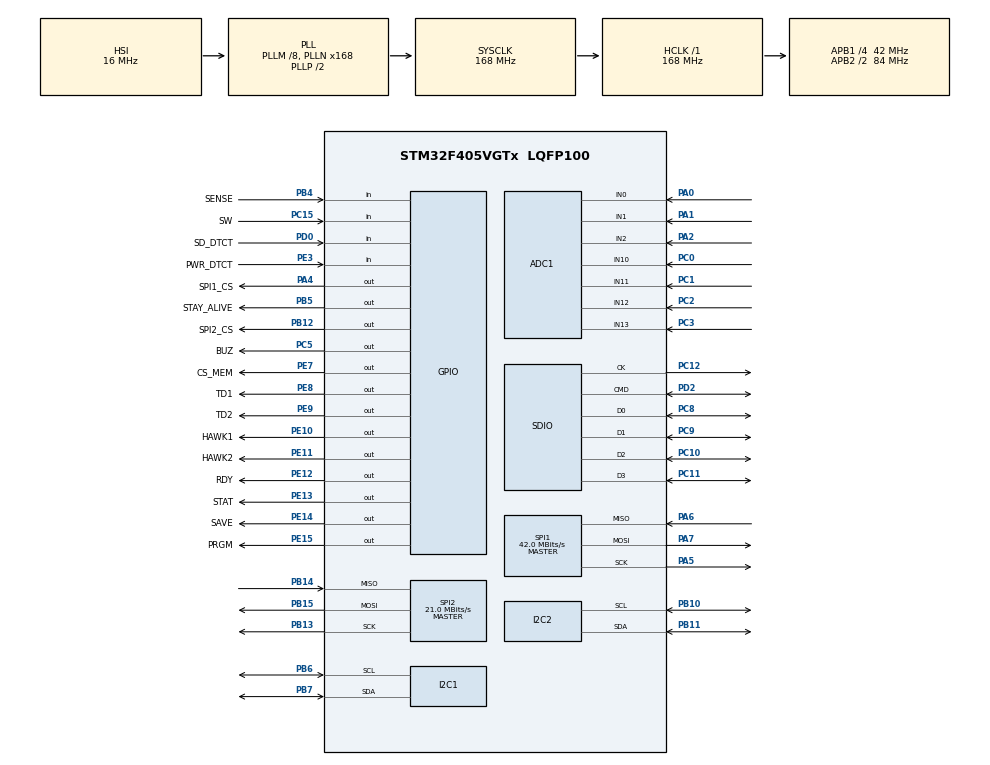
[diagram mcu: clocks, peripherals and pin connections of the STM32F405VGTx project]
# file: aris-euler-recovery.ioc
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ADC1.Channel-0\#ChannelRegularConversion=ADC_CHANNEL_0
ADC1.Channel-1\#ChannelRegularConversion=ADC_CHANNEL_1
ADC1.Channel-2\#ChannelRegularConversion=ADC_CHANNEL_2
ADC1.Channel-3\#ChannelRegularConversion=ADC_CHANNEL_10
ADC1.Channel-4\#ChannelRegularConversion=ADC_CHANNEL_11
ADC1.Channel-5\#ChannelRegularConversion=ADC_CHANNEL_12
ADC1.Channel-6\#ChannelRegularConversion=ADC_CHANNEL_13
ADC1.Channel-7\#ChannelRegularConversion=ADC_CHANNEL_TEMPSENSOR
ADC1.ContinuousConvMode=ENABLE
ADC1.DMAContinuousRequests=ENABLE
ADC1.NbrOfConversion=8
ADC1.NbrOfConversionFlag=1
ADC1.Rank-0\#ChannelRegularConversion=1
ADC1.Rank-1\#ChannelRegularConversion=2
ADC1.Rank-2\#ChannelRegularConversion=3
ADC1.Rank-3\#ChannelRegularConversion=4
ADC1.Rank-4\#ChannelRegularConversion=5
ADC1.Rank-5\#ChannelRegularConversion=6
ADC1.Rank-6\#ChannelRegularConversion=7
ADC1.Rank-7\#ChannelRegularConversion=8
ADC1.SamplingTime-0\#ChannelRegularConversion=ADC_SAMPLETIME_480CYCLES
ADC1.SamplingTime-1\#ChannelRegularConversion=ADC_SAMPLETIME_480CYCLES
ADC1.SamplingTime-2\#ChannelRegularConversion=ADC_SAMPLETIME_480CYCLES
ADC1.SamplingTime-3\#ChannelRegularConversion=ADC_SAMPLETIME_480CYCLES
ADC1.SamplingTime-4\#ChannelRegularConversion=ADC_SAMPLETIME_480CYCLES
ADC1.SamplingTime-5\#ChannelRegularConversion=ADC_SAMPLETIME_480CYCLES
ADC1.SamplingTime-6\#ChannelRegularConversion=ADC_SAMPLETIME_480CYCLES
ADC1.SamplingTime-7\#ChannelRegularConversion=ADC_SAMPLETIME_480CYCLES
ADC1.ScanConvMode=ENABLE
ADC1.master=1
Dma.ADC1.0.Direction=DMA_PERIPH_TO_MEMORY
Dma.ADC1.0.FIFOMode=DMA_FIFOMODE_DISABLE
Dma.ADC1.0.Instance=DMA2_Stream0
Dma.ADC1.0.MemDataAlignment=DMA_MDATAALIGN_WORD
Dma.ADC1.0.MemInc=DMA_MINC_ENABLE
Dma.ADC1.0.Mode=DMA_CIRCULAR
Dma.ADC1.0.PeriphDataAlignment=DMA_PDATAALIGN_WORD
Dma.ADC1.0.PeriphInc=DMA_PINC_DISABLE
Dma.ADC1.0.Priority=DMA_PRIORITY_LOW
Dma.Request0=ADC1
Dma.Request1=SDIO_RX
Dma.Request2=SDIO_TX
Dma.SDIO_RX.1.Direction=DMA_PERIPH_TO_MEMORY
Dma.SDIO_RX.1.FIFOMode=DMA_FIFOMODE_ENABLE
Dma.SDIO_RX.1.FIFOThreshold=DMA_FIFO_THRESHOLD_FULL
Dma.SDIO_RX.1.Instance=DMA2_Stream3
Dma.SDIO_RX.1.MemBurst=DMA_MBURST_INC4
Dma.SDIO_RX.1.MemDataAlignment=DMA_MDATAALIGN_WORD
Dma.SDIO_RX.1.MemInc=DMA_MINC_ENABLE
Dma.SDIO_RX.1.Mode=DMA_PFCTRL
Dma.SDIO_RX.1.PeriphBurst=DMA_PBURST_INC4
Dma.SDIO_RX.1.PeriphDataAlignment=DMA_PDATAALIGN_WORD
Dma.SDIO_RX.1.PeriphInc=DMA_PINC_DISABLE
Dma.SDIO_RX.1.Priority=DMA_PRIORITY_LOW
Dma.SDIO_TX.2.Direction=DMA_MEMORY_TO_PERIPH
Dma.SDIO_TX.2.FIFOMode=DMA_FIFOMODE_ENABLE
Dma.SDIO_TX.2.FIFOThreshold=DMA_FIFO_THRESHOLD_FULL
Dma.SDIO_TX.2.Instance=DMA2_Stream6
Dma.SDIO_TX.2.MemBurst=DMA_MBURST_INC4
Dma.SDIO_TX.2.MemDataAlignment=DMA_MDATAALIGN_WORD
Dma.SDIO_TX.2.MemInc=DMA_MINC_ENABLE
Dma.SDIO_TX.2.Mode=DMA_PFCTRL
Dma.SDIO_TX.2.PeriphBurst=DMA_PBURST_INC4
Dma.SDIO_TX.2.PeriphDataAlignment=DMA_PDATAALIGN_WORD
Dma.SDIO_TX.2.PeriphInc=DMA_PINC_DISABLE
Dma.SDIO_TX.2.Priority=DMA_PRIORITY_LOW
FATFS.BSP.number=1
FATFS.USE_DMA_CODE_SD=1
FATFS._FS_TINY=0
FATFS._MAX_SS=4096
FATFS0.BSP.STBoard=false
FATFS0.BSP.api=Unknown
FATFS0.BSP.i2caddr=0
FATFS0.BSP.instance=PD0
FATFS0.BSP.ip=GPIO
FATFS0.BSP.mode=Input
FATFS0.BSP.name=Detect_SDIO
FATFS0.BSP.solution=PD0
I2C1.I2C_Mode=I2C_Fast
Mcu.Family=STM32F4
Mcu.Name=STM32F405VGTx
Mcu.Package=LQFP100
NVIC.DMA2_Stream0_IRQn=true\:0\:0\:false\:false\:true\:false\:true
NVIC.DMA2_Stream3_IRQn=true\:0\:0\:false\:false\:true\:false\:true
NVIC.DMA2_Stream6_IRQn=true\:0\:0\:false\:false\:true\:false\:true
NVIC.PriorityGroup=NVIC_PRIORITYGROUP_4
NVIC.SDIO_IRQn=true\:0\:0\:false\:false\:true\:true\:true
PA0-WKUP.Signal=ADCx_IN0
PA1.Signal=ADCx_IN1
PA13.Mode=Trace_Asynchronous_SW
PA13.Signal=SYS_JTMS-SWDIO
PA14.Mode=Trace_Asynchronous_SW
PA14.Signal=SYS_JTCK-SWCLK
PA2.Signal=ADCx_IN2
PA4.GPIO_Label=SPI1_CS
PA4.Signal=GPIO_Output
PA5.Mode=Full_Duplex_Master
PA5.Signal=SPI1_SCK
PA6.Mode=Full_Duplex_Master
PA6.Signal=SPI1_MISO
PA7.Mode=Full_Duplex_Master
PA7.Signal=SPI1_MOSI
PB10.Mode=I2C
PB10.Signal=I2C2_SCL
PB11.Mode=I2C
PB11.Signal=I2C2_SDA
PB12.GPIO_Label=SPI2_CS
PB12.Signal=GPIO_Output
PB13.Mode=Full_Duplex_Master
PB13.Signal=SPI2_SCK
PB14.Mode=Full_Duplex_Master
PB14.Signal=SPI2_MISO
PB15.Mode=Full_Duplex_Master
PB15.Signal=SPI2_MOSI
PB3.Mode=Trace_Asynchronous_SW
PB3.Signal=SYS_JTDO-SWO
PB4.GPIO_Label=SENSE
PB4.Signal=GPIO_Input
PB5.GPIO_Label=STAY_ALIVE
PB5.Signal=GPIO_Output
PB6.Mode=I2C
PB6.Signal=I2C1_SCL
PB7.Mode=I2C
PB7.Signal=I2C1_SDA
PC0.Signal=ADCx_IN10
PC1.Signal=ADCx_IN11
PC10.Mode=SD_4_bits_Wide_bus
PC10.Signal=SDIO_D2
PC11.Mode=SD_4_bits_Wide_bus
PC11.Signal=SDIO_D3
PC12.Mode=SD_4_bits_Wide_bus
PC12.Signal=SDIO_CK
PC15-OSC32_OUT.GPIO_Label=SW
PC15-OSC32_OUT.Signal=GPIO_Input
PC2.Signal=ADCx_IN12
PC3.Signal=ADCx_IN13
PC5.GPIO_Label=BUZ
PC5.Signal=GPIO_Output
PC8.Mode=SD_4_bits_Wide_bus
PC8.Signal=SDIO_D0
PC9.Mode=SD_4_bits_Wide_bus
PC9.Signal=SDIO_D1
PD0.GPIO_Label=SD_DTCT
PD0.Signal=GPIO_Input
PD2.Mode=SD_4_bits_Wide_bus
PD2.Signal=SDIO_CMD
PE10.GPIO_Label=HAWK1
PE10.Signal=GPIO_Output
PE11.GPIO_Label=HAWK2
PE11.Signal=GPIO_Output
PE12.GPIO_Label=RDY
PE12.Signal=GPIO_Output
PE13.GPIO_Label=STAT
PE13.Signal=GPIO_Output
PE14.GPIO_Label=SAVE
PE14.Signal=GPIO_Output
PE15.GPIO_Label=PRGM
PE15.Signal=GPIO_Output
PE3.GPIO_Label=PWR_DTCT
PE3.Signal=GPIO_Input
PE7.GPIO_Label=CS_MEM
PE7.Signal=GPIO_Output
PE8.GPIO_Label=TD1
PE8.Signal=GPIO_Output
PE9.GPIO_Label=TD2
PE9.Signal=GPIO_Output
ProjectManager.HeapSize=0x200
ProjectManager.StackSize=0x2048
ProjectManager.TargetToolchain=STM32CubeIDE
RCC.48MHZClocksFreq_Value=48000000
RCC.AHBFreq_Value=168000000
RCC.APB1CLKDivider=RCC_HCLK_DIV4
RCC.APB1Freq_Value=42000000
RCC.APB1TimFreq_Value=84000000
RCC.APB2CLKDivider=RCC_HCLK_DIV2
RCC.APB2Freq_Value=84000000
RCC.APB2TimFreq_Value=168000000
RCC.CortexFreq_Value=168000000
RCC.HCLKFreq_Value=168000000
RCC.HSE_VALUE=25000000
RCC.HSI_VALUE=16000000
RCC.LSE_VALUE=32768
RCC.PLLM=8
RCC.PLLN=168
RCC.PLLQ=7
RCC.SYSCLKFreq_VALUE=168000000
RCC.SYSCLKSource=RCC_SYSCLKSOURCE_PLLCLK
RCC.VCOOutputFreq_Value=336000000
SDIO.ClockDiv=3
SH.ADCx_IN0.0=ADC1_IN0,IN0
SH.ADCx_IN1.0=ADC1_IN1,IN1
SH.ADCx_IN10.0=ADC1_IN10,IN10
SH.ADCx_IN11.0=ADC1_IN11,IN11
SH.ADCx_IN12.0=ADC1_IN12,IN12
SH.ADCx_IN13.0=ADC1_IN13,IN13
SH.ADCx_IN2.0=ADC1_IN2,IN2
SPI1.CalculateBaudRate=42.0 MBits/s
SPI1.Direction=SPI_DIRECTION_2LINES
SPI1.Mode=SPI_MODE_MASTER
SPI1.VirtualType=VM_MASTER
SPI2.BaudRatePrescaler=SPI_BAUDRATEPRESCALER_2
SPI2.CLKPhase=SPI_PHASE_1EDGE
SPI2.CalculateBaudRate=21.0 MBits/s
SPI2.Direction=SPI_DIRECTION_2LINES
SPI2.Mode=SPI_MODE_MASTER
SPI2.VirtualType=VM_MASTER
VP_ADC1_TempSens_Input.Mode=IN-TempSens
VP_FATFS_VS_SDIO.Mode=SDIO
board=custom

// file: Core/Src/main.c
/* USER CODE BEGIN Header */
/**
  ******************************************************************************
  * @file           : main.c
  * @brief          : Main program body
  ******************************************************************************
  * @attention
  *
  * <h2><center>&copy; Copyright (c) 2020 STMicroelectronics.
  * All rights reserved.</center></h2>
  *
  * This software component is licensed by ST under BSD 3-Clause license,
  * the "License"; You may not use this file except in compliance with the
  * License. You may obtain a copy of the License at:
  *                        opensource.org/licenses/BSD-3-Clause
  *
  ******************************************************************************
  */
/* USER CODE END Header */
#include "main.h"
#include "adc.h"
#include "dma.h"
#include "fatfs.h"
#include "i2c.h"
#include "sdio.h"
#include "spi.h"
#include "gpio.h"

/* USER CODE BEGIN Includes */

#include "IO.h"
#include "manager.h"

#include <string.h>
#include <stdio.h>
#include <math.h>

/* USER CODE END Includes */

void SystemClock_Config(void);

int main(void)
{

  /* MCU Configuration--------------------------------------------------------*/

  /* Reset of all peripherals, Initializes the Flash interface and the Systick. */
  HAL_Init();

  /* Configure the system clock */
  SystemClock_Config();

  /* Initialize all configured peripherals */
  MX_GPIO_Init();
  MX_DMA_Init();
  MX_I2C1_Init();
  MX_SPI2_Init();
  MX_ADC1_Init();
  MX_I2C2_Init();
  MX_SDIO_SD_Init();
  MX_SPI1_Init();
  MX_FATFS_Init();
  /* USER CODE BEGIN 2 */

  turn_off_HAWKs();
  turn_off_TDs();

  schedulerinit();

  /* USER CODE END 2 */

  /* Infinite loop */
  while (1)
  {

    /* USER CODE BEGIN 3 */

	scheduler();

  }
  /* USER CODE END 3 */
}

void SystemClock_Config(void)
{
  RCC_OscInitTypeDef RCC_OscInitStruct = {0};
  RCC_ClkInitTypeDef RCC_ClkInitStruct = {0};

  /** Configure the main internal regulator output voltage
  */
  __HAL_RCC_PWR_CLK_ENABLE();
  __HAL_PWR_VOLTAGESCALING_CONFIG(PWR_REGULATOR_VOLTAGE_SCALE1);
  /** Initializes the RCC Oscillators according to the specified parameters
  * in the RCC_OscInitTypeDef structure.
  */
  RCC_OscInitStruct.OscillatorType = RCC_OSCILLATORTYPE_HSI;
  RCC_OscInitStruct.HSIState = RCC_HSI_ON;
  RCC_OscInitStruct.HSICalibrationValue = RCC_HSICALIBRATION_DEFAULT;
  RCC_OscInitStruct.PLL.PLLState = RCC_PLL_ON;
  RCC_OscInitStruct.PLL.PLLSource = RCC_PLLSOURCE_HSI;
  RCC_OscInitStruct.PLL.PLLM = 8;
  RCC_OscInitStruct.PLL.PLLN = 168;
  RCC_OscInitStruct.PLL.PLLP = RCC_PLLP_DIV2;
  RCC_OscInitStruct.PLL.PLLQ = 7;
  if (HAL_RCC_OscConfig(&RCC_OscInitStruct) != HAL_OK)
  {
    Error_Handler();
  }
  /** Initializes the CPU, AHB and APB buses clocks
  */
  RCC_ClkInitStruct.ClockType = RCC_CLOCKTYPE_HCLK|RCC_CLOCKTYPE_SYSCLK
                              |RCC_CLOCKTYPE_PCLK1|RCC_CLOCKTYPE_PCLK2;
  RCC_ClkInitStruct.SYSCLKSource = RCC_SYSCLKSOURCE_PLLCLK;
  RCC_ClkInitStruct.AHBCLKDivider = RCC_SYSCLK_DIV1;
  RCC_ClkInitStruct.APB1CLKDivider = RCC_HCLK_DIV4;
  RCC_ClkInitStruct.APB2CLKDivider = RCC_HCLK_DIV2;

  if (HAL_RCC_ClockConfig(&RCC_ClkInitStruct, FLASH_LATENCY_5) != HAL_OK)
  {
    Error_Handler();
  }
}

void Error_Handler(void)
{
}

/************************ (C) COPYRIGHT STMicroelectronics *****END OF FILE****/
